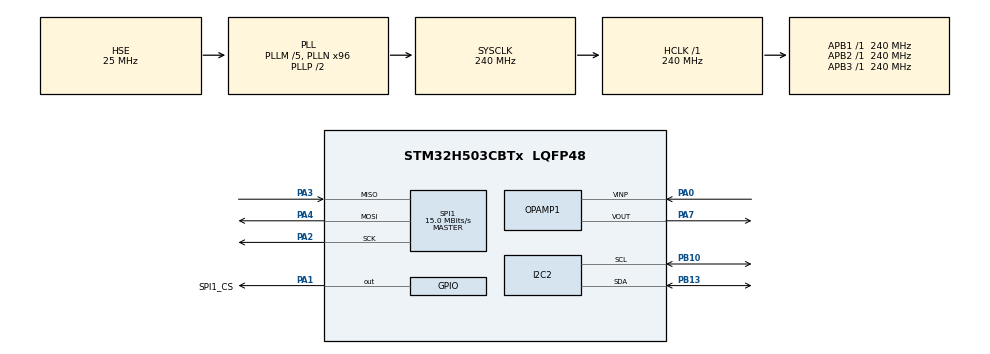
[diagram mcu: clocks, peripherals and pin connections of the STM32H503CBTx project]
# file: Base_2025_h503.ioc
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ADC1.Channel-0\#ChannelRegularConversion=ADC_CHANNEL_7
ADC1.ConversionDataManagement=ADC_CONVERSIONDATA_DMA_CIRCULAR
ADC1.DMAContinuousRequests=ENABLE
ADC1.ExternalTrigConv=ADC_EXTERNALTRIG_T2_TRGO
ADC1.MonitoredBy-0\#ChannelRegularConversion=__NULL
ADC1.NbrOfConversionFlag=1
ADC1.OffsetNumber-0\#ChannelRegularConversion=ADC_OFFSET_NONE
ADC1.Rank-0\#ChannelRegularConversion=1
ADC1.SamplingTime-0\#ChannelRegularConversion=ADC_SAMPLETIME_2CYCLES_5
ADC1.master=1
BOOTPATH.BootPathName=LEGACY
BOOTPATH.UserSelectedBootPath=LEGACY
CORTEX_M33_NS.Number-Cortex_Memory_Protection_Unit_Region0_OTP_RO_AREAS_Settings=MPU_REGION_NUMBER0
CORTEX_M33_NS.default_mode_Activation=1
GPDMA1.CIRCULARMODE_GPDMACH1=ENABLE
GPDMA1.DESTDATAWIDTH_GPDMACH1=DMA_DEST_DATAWIDTH_HALFWORD
GPDMA1.DESTINC_GPDMACH1=DMA_DINC_INCREMENTED
GPDMA1.DIRECTION_GPDMACH0=DMA_MEMORY_TO_PERIPH
GPDMA1.IPHANDLE_GPDMACH0-SIMPLEREQUEST_GPDMACH0=__NULL
GPDMA1.IPHANDLE_GPDMACH1-SIMPLEREQUEST_GPDMACH1=__NULL
GPDMA1.PRIORITY_LL_CIRCULAR_GPDMACH1=DMA_LOW_PRIORITY_HIGH_WEIGHT
GPDMA1.RECAP_GPDMACH0=GPDMA1_REQUEST_SPI1_TX
GPDMA1.REQUEST_GPDMACH0=GPDMA1_REQUEST_SPI1_TX
GPDMA1.REQUEST_GPDMACH1=GPDMA1_REQUEST_ADC1
GPDMA1.SRCDATAWIDTH_GPDMACH1=DMA_SRC_DATAWIDTH_HALFWORD
GPDMA1.SRCINC_GPDMACH0=DMA_SINC_INCREMENTED
I2C2.Timing=0x608087CA
Mcu.Family=STM32H5
Mcu.Name=STM32H503CBTx
Mcu.Package=LQFP48
NVIC.GPDMA1_Channel0_IRQn=true\:0\:0\:false\:false\:true\:true\:true\:true
NVIC.GPDMA1_Channel1_IRQn=true\:0\:0\:false\:false\:true\:false\:true\:true
NVIC.PriorityGroup=NVIC_PRIORITYGROUP_4
PA0.Mode=Follower
PA0.Signal=OPAMP1_VINP
PA1.GPIO_Label=SPI1_CS
PA1.PinState=GPIO_PIN_SET
PA1.Signal=GPIO_Output
PA13(JTMS/SWDIO).Mode=Serial_Wire
PA13(JTMS/SWDIO).Signal=DEBUG_JTMS-SWDIO
PA14(JTCK/SWCLK).Mode=Serial_Wire
PA14(JTCK/SWCLK).Signal=DEBUG_JTCK-SWCLK
PA2.Mode=Full_Duplex_Master
PA2.Signal=SPI1_SCK
PA3.Mode=Full_Duplex_Master
PA3.Signal=SPI1_MISO
PA4.Mode=Full_Duplex_Master
PA4.Signal=SPI1_MOSI
PA7.Signal=SharedAnalog_PA7
PB10.Mode=I2C
PB10.Signal=I2C2_SCL
PB13.Mode=I2C
PB13.Signal=I2C2_SDA
PC14-OSC32_IN(OSC32_IN).Mode=LSE-External-Oscillator
PC14-OSC32_IN(OSC32_IN).Signal=RCC_OSC32_IN
PC15-OSC32_OUT(OSC32_OUT).Mode=LSE-External-Oscillator
PC15-OSC32_OUT(OSC32_OUT).Signal=RCC_OSC32_OUT
PH0-OSC_IN(PH0).Mode=HSE-External-Oscillator
PH0-OSC_IN(PH0).Signal=RCC_OSC_IN
PH1-OSC_OUT(PH1).Mode=HSE-External-Oscillator
PH1-OSC_OUT(PH1).Signal=RCC_OSC_OUT
ProjectManager.HeapSize=0x200
ProjectManager.StackSize=0x400
ProjectManager.TargetToolchain=MDK-ARM V5.37
RCC.ADCFreq_Value=240000000
RCC.AHBFreq_Value=240000000
RCC.APB1Freq_Value=240000000
RCC.APB1TimFreq_Value=240000000
RCC.APB2Freq_Value=240000000
RCC.APB2TimFreq_Value=240000000
RCC.APB3Freq_Value=240000000
RCC.CSI_VALUE=4000000
RCC.CortexFreq_Value=240000000
RCC.EPOD_VALUE=25000000
RCC.HCLKFreq_Value=240000000
RCC.HSE_VALUE=25000000
RCC.HSI48_VALUE=48000000
RCC.HSI_VALUE=64000000
RCC.LSIRC_VALUE=32000
RCC.PLL2FRACN=0
RCC.PLL2N=99
RCC.PLL2R=33
RCC.PLL2Source=RCC_PLL2_SOURCE_HSE
RCC.PLLFRACN=0
RCC.PLLM=5
RCC.PLLN=96
RCC.PLLSourceVirtual=RCC_PLL1_SOURCE_HSE
RCC.SYSCLKFreq_VALUE=240000000
RCC.SYSCLKSource=RCC_SYSCLKSOURCE_PLLCLK
RCC.USBFreq_Value=48000000
RCC.VCOOutputFreq_Value=480000000
SH.SharedAnalog_PA7.0=OPAMP1_VOUT,Follower
SH.SharedAnalog_PA7.1=ADC1_INP7,IN7-Single-Ended
SPI1.BaudRatePrescaler=SPI_BAUDRATEPRESCALER_16
SPI1.CLKPhase=SPI_PHASE_1EDGE
SPI1.CLKPolarity=SPI_POLARITY_HIGH
SPI1.CalculateBaudRate=15.0 MBits/s
SPI1.DataSize=SPI_DATASIZE_8BIT
SPI1.Direction=SPI_DIRECTION_2LINES
SPI1.Mode=SPI_MODE_MASTER
SPI1.VirtualType=VM_MASTER
STMicroelectronics.X-CUBE-ALGOBUILD.1.3.0.LibraryCcDSPOoLibraryJjDSPOoLibrary=true
TIM2.AutoReloadPreload=TIM_AUTORELOAD_PRELOAD_ENABLE
TIM2.PeriodNoDither=7499
TIM2.Prescaler=0
TIM2.TIM_MasterOutputTrigger=TIM_TRGO_UPDATE
VP_BOOTPATH_VS_BOOTPATH.Mode=BP_Activate
VP_CORTEX_M33_NS_VS_Hclk.Mode=Hclk_Mode
VP_GPDMA1_VS_GPDMACH0.Mode=SIMPLEREQUEST_GPDMACH0
VP_GPDMA1_VS_GPDMACH1.Mode=SIMPLEREQUEST_GPDMACH1
VP_ICACHE_VS_ICACHE.Mode=DirectMappedCache
VP_MEMORYMAP_VS_MEMORYMAP.Mode=CurAppReg
VP_PWR_VS_LPOM.Mode=PowerOptimisation
VP_PWR_VS_SECSignals.Mode=Security/Privilege
VP_STMicroelectronics.X-CUBE-ALGOBUILD_VS_DSPOoLibraryJjLibrary_1.3.0_1.3.0.Mode=DSPOoLibraryJjLibrary
VP_TIM2_VS_ClockSourceINT.Mode=Internal
board=custom

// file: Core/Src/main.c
/* USER CODE BEGIN Header */
/**
  ******************************************************************************
  * @file           : main.c
  * @brief          : Main program body
  ******************************************************************************
  * @attention
  *
  * Copyright (c) 2026 STMicroelectronics.
  * All rights reserved.
  *
  * This software is licensed under terms that can be found in the LICENSE file
  * in the root directory of this software component.
  * If no LICENSE file comes with this software, it is provided AS-IS.
  *
  ******************************************************************************
  */
/* USER CODE END Header */
#include "main.h"
#include "adc.h"
#include "gpdma.h"
#include "i2c.h"
#include "icache.h"
#include "opamp.h"
#include "spi.h"
#include "tim.h"
#include "gpio.h"

/* USER CODE BEGIN Includes */
#include "oled.h"
#include "spi.h"
#include "ad9833.h"
#include <stdio.h>
/* USER CODE END Includes */

void SystemClock_Config(void);
static void MPU_Config(void);

int main(void)
{

  /* MCU Configuration--------------------------------------------------------*/

  /* MPU Configuration--------------------------------------------------------*/
  MPU_Config();

  /* Reset of all peripherals, Initializes the Flash interface and the Systick. */
  HAL_Init();

  /* Configure the system clock */
  SystemClock_Config();

  /* Initialize all configured peripherals */
  MX_GPIO_Init();
  MX_GPDMA1_Init();
  MX_ICACHE_Init();
  MX_I2C2_Init();
  MX_SPI1_Init();
  MX_OPAMP1_Init();
  MX_ADC1_Init();
  MX_TIM2_Init();
  /* USER CODE BEGIN 2 */
  OLED_Init();
  OLED_Clear();

  AD9833_Init();
  uint32_t freq_hz = 100000;
  AD9833_SetFrequency(freq_hz);

  OLED_ShowString(0, 0, "--- AD9833 DDS ---");
  OLED_Printf(0, 16, "Wave: Sine");
  OLED_Printf(0, 32, "Freq: %lu Hz", (unsigned long)freq_hz);
  OLED_DisplayFast();
  /* USER CODE END 2 */

  /* Infinite loop */
  while (1)
  {

  }
}

void SystemClock_Config(void)
{
  RCC_OscInitTypeDef RCC_OscInitStruct = {0};
  RCC_ClkInitTypeDef RCC_ClkInitStruct = {0};

  /** Configure the main internal regulator output voltage
  */
  __HAL_PWR_VOLTAGESCALING_CONFIG(PWR_REGULATOR_VOLTAGE_SCALE0);

  while(!__HAL_PWR_GET_FLAG(PWR_FLAG_VOSRDY)) {}

  /** Initializes the RCC Oscillators according to the specified parameters
  * in the RCC_OscInitTypeDef structure.
  */
  RCC_OscInitStruct.OscillatorType = RCC_OSCILLATORTYPE_HSE;
  RCC_OscInitStruct.HSEState = RCC_HSE_ON;
  RCC_OscInitStruct.PLL.PLLState = RCC_PLL_ON;
  RCC_OscInitStruct.PLL.PLLSource = RCC_PLL1_SOURCE_HSE;
  RCC_OscInitStruct.PLL.PLLM = 5;
  RCC_OscInitStruct.PLL.PLLN = 96;
  RCC_OscInitStruct.PLL.PLLP = 2;
  RCC_OscInitStruct.PLL.PLLQ = 2;
  RCC_OscInitStruct.PLL.PLLR = 2;
  RCC_OscInitStruct.PLL.PLLRGE = RCC_PLL1_VCIRANGE_2;
  RCC_OscInitStruct.PLL.PLLVCOSEL = RCC_PLL1_VCORANGE_WIDE;
  RCC_OscInitStruct.PLL.PLLFRACN = 0;
  if (HAL_RCC_OscConfig(&RCC_OscInitStruct) != HAL_OK)
  {
    Error_Handler();
  }

  /** Initializes the CPU, AHB and APB buses clocks
  */
  RCC_ClkInitStruct.ClockType = RCC_CLOCKTYPE_HCLK|RCC_CLOCKTYPE_SYSCLK
                              |RCC_CLOCKTYPE_PCLK1|RCC_CLOCKTYPE_PCLK2
                              |RCC_CLOCKTYPE_PCLK3;
  RCC_ClkInitStruct.SYSCLKSource = RCC_SYSCLKSOURCE_PLLCLK;
  RCC_ClkInitStruct.AHBCLKDivider = RCC_SYSCLK_DIV1;
  RCC_ClkInitStruct.APB1CLKDivider = RCC_HCLK_DIV1;
  RCC_ClkInitStruct.APB2CLKDivider = RCC_HCLK_DIV1;
  RCC_ClkInitStruct.APB3CLKDivider = RCC_HCLK_DIV1;

  if (HAL_RCC_ClockConfig(&RCC_ClkInitStruct, FLASH_LATENCY_5) != HAL_OK)
  {
    Error_Handler();
  }

  /** Configure the programming delay
  */
  __HAL_FLASH_SET_PROGRAM_DELAY(FLASH_PROGRAMMING_DELAY_2);
}

 /* MPU Configuration */

void MPU_Config(void)
{
  MPU_Region_InitTypeDef MPU_InitStruct = {0};
  MPU_Attributes_InitTypeDef MPU_AttributesInit = {0};

  /* Disables the MPU */
  HAL_MPU_Disable();

  /** Initializes and configures the Region 0 and the memory to be protected
  */
  MPU_InitStruct.Enable = MPU_REGION_ENABLE;
  MPU_InitStruct.Number = MPU_REGION_NUMBER0;
  MPU_InitStruct.BaseAddress = 0x08FFF000;
  MPU_InitStruct.LimitAddress = 0x08FFFFFF;
  MPU_InitStruct.AttributesIndex = MPU_ATTRIBUTES_NUMBER0;
  MPU_InitStruct.AccessPermission = MPU_REGION_ALL_RO;
  MPU_InitStruct.DisableExec = MPU_INSTRUCTION_ACCESS_DISABLE;
  MPU_InitStruct.IsShareable = MPU_ACCESS_NOT_SHAREABLE;

  HAL_MPU_ConfigRegion(&MPU_InitStruct);

  /** Initializes and configures the Attribute 0 and the memory to be protected
  */
  MPU_AttributesInit.Number = MPU_ATTRIBUTES_NUMBER0;
  MPU_AttributesInit.Attributes = INNER_OUTER(MPU_NOT_CACHEABLE);

  HAL_MPU_ConfigMemoryAttributes(&MPU_AttributesInit);
  /* Enables the MPU */
  HAL_MPU_Enable(MPU_PRIVILEGED_DEFAULT);

}

void Error_Handler(void)
{
  __disable_irq();
  while (1)
  {
  }
}
